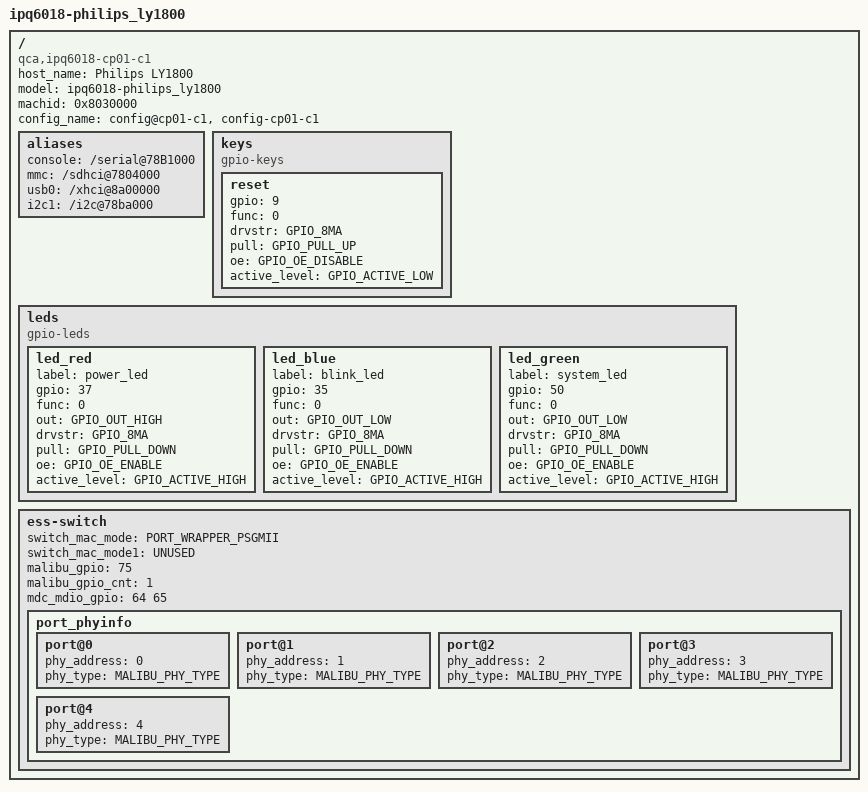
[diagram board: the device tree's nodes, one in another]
/*
 * Copyright (c) 2019, The Linux Foundation. All rights reserved.
 *
 * This program is free software; you can redistribute it and/or modify
 * it under the terms of the GNU General Public License version 2 and
 * only version 2 as published by the Free Software Foundation.
 *
 * This program is distributed in the hope that it will be useful,
 * but WITHOUT ANY WARRANTY; without even the implied warranty of
 * MERCHANTABILITY or FITNESS FOR A PARTICULAR PURPOSE.  See the
 * GNU General Public License for more details.
 */

/dts-v1/;
#include "ipq6018-soc.dtsi"
/ {
	host_name = "Philips LY1800";
	model = "ipq6018-philips_ly1800";
	compatible = "qca,ipq6018-cp01-c1", "qca,ipq6018";
	machid = <0x8030000>;
	config_name = "config@cp01-c1", "config-cp01-c1";

	aliases {
		console = "/serial@78B1000";
		mmc = "/sdhci@7804000";
		usb0 = "/xhci@8a00000";
		i2c1 = "/i2c@78ba000";
	};

	keys {
		compatible = "gpio-keys";

		reset {
			gpio = <9>;
			func = <0>;
			drvstr = <GPIO_8MA>;
			pull = <GPIO_PULL_UP>;
			oe = <GPIO_OE_DISABLE>;
			active_level = <GPIO_ACTIVE_LOW>;
		};
	};

	leds {
		compatible = "gpio-leds";

		led_red {
			label = "power_led";
			gpio = <37>;
			func = <0>;
			out = <GPIO_OUT_HIGH>;
			drvstr = <GPIO_8MA>;
			pull = <GPIO_PULL_DOWN>;
			oe = <GPIO_OE_ENABLE>;
			active_level = <GPIO_ACTIVE_HIGH>;
		};

		led_blue {
			label = "blink_led";
			gpio = <35>;
			func = <0>;
			out = <GPIO_OUT_LOW>;
			drvstr = <GPIO_8MA>;
			pull = <GPIO_PULL_DOWN>;
			oe = <GPIO_OE_ENABLE>;
			active_level = <GPIO_ACTIVE_HIGH>;
		};

		led_green {
			label = "system_led";
			gpio = <50>;
			func = <0>;
			out = <GPIO_OUT_LOW>;
			drvstr = <GPIO_8MA>;
			pull = <GPIO_PULL_DOWN>;
			oe = <GPIO_OE_ENABLE>;
			active_level = <GPIO_ACTIVE_HIGH>;
		};
	};

	ess-switch {
		switch_mac_mode = <PORT_WRAPPER_PSGMII>;
		switch_mac_mode1 = <UNUSED>;
		malibu_gpio = <75>;
		malibu_gpio_cnt = <1>;
		mdc_mdio_gpio = <64 65>;
		port_phyinfo {
			port@0 {
				phy_address = <0>;
				phy_type = <MALIBU_PHY_TYPE>;
			};
			port@1 {
				phy_address = <1>;
				phy_type = <MALIBU_PHY_TYPE>;
			};
			port@2 {
				phy_address = <2>;
				phy_type = <MALIBU_PHY_TYPE>;
			};
			port@3 {
				phy_address = <3>;
				phy_type = <MALIBU_PHY_TYPE>;
			};
			port@4 {
				phy_address = <4>;
				phy_type = <MALIBU_PHY_TYPE>;
			};
		};
	};
};
